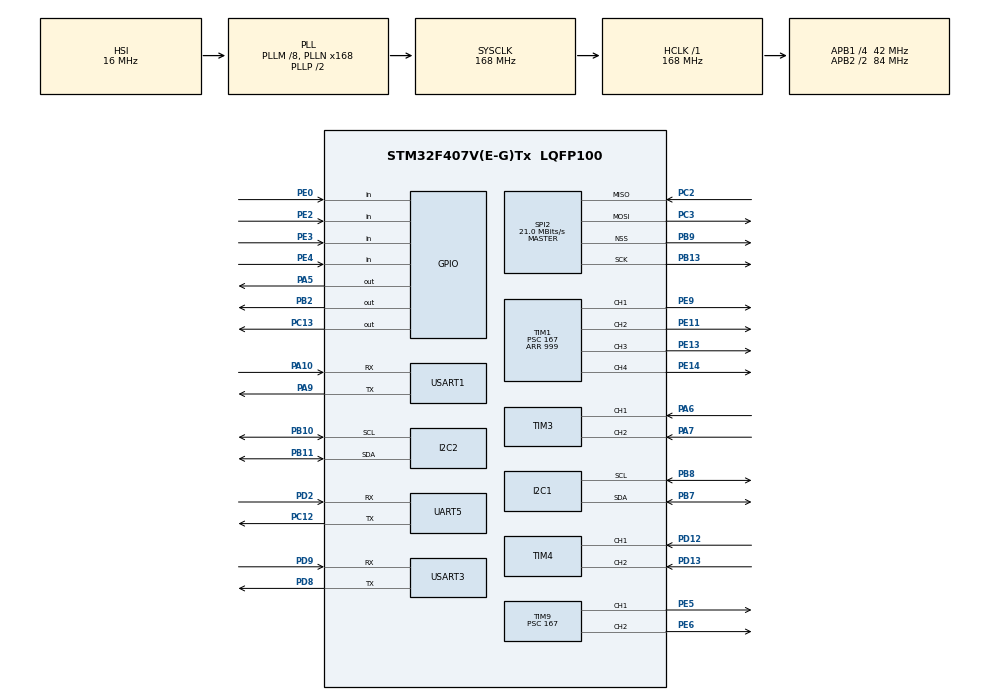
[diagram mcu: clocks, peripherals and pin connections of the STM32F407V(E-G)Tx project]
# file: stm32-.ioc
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Mcu.Family=STM32F4
Mcu.Name=STM32F407V(E-G)Tx
Mcu.Package=LQFP100
NVIC.PriorityGroup=NVIC_PRIORITYGROUP_4
NVIC.TIM8_BRK_TIM12_IRQn=true\:0\:0\:false\:false\:true\:true\:true\:true
NVIC.UART5_IRQn=true\:0\:0\:false\:false\:true\:true\:true\:true
NVIC.USART1_IRQn=true\:0\:0\:false\:false\:true\:true\:true\:true
NVIC.USART3_IRQn=true\:0\:0\:false\:false\:true\:true\:true\:true
PA0-WKUP.Signal=S_TIM2_CH1_ETR
PA1.Signal=S_TIM2_CH2
PA10.Mode=Asynchronous
PA10.Signal=USART1_RX
PA5.Signal=GPIO_Output
PA6.Signal=S_TIM3_CH1
PA7.Signal=S_TIM3_CH2
PA9.Mode=Asynchronous
PA9.Signal=USART1_TX
PB10.Mode=I2C
PB10.Signal=I2C2_SCL
PB11.Mode=I2C
PB11.Signal=I2C2_SDA
PB13.Mode=Full_Duplex_Master
PB13.Signal=SPI2_SCK
PB2.Signal=GPIO_Output
PB7.Mode=I2C
PB7.Signal=I2C1_SDA
PB8.Mode=I2C
PB8.Signal=I2C1_SCL
PB9.Mode=NSS_Signal_Hard_Output
PB9.Signal=SPI2_NSS
PC12.Mode=Asynchronous
PC12.Signal=UART5_TX
PC13-ANTI_TAMP.PinState=GPIO_PIN_RESET
PC13-ANTI_TAMP.Signal=GPIO_Output
PC2.Mode=Full_Duplex_Master
PC2.Signal=SPI2_MISO
PC3.Mode=Full_Duplex_Master
PC3.Signal=SPI2_MOSI
PD12.Signal=S_TIM4_CH1
PD13.Signal=S_TIM4_CH2
PD2.Mode=Asynchronous
PD2.Signal=UART5_RX
PD8.Mode=Asynchronous
PD8.Signal=USART3_TX
PD9.Mode=Asynchronous
PD9.Signal=USART3_RX
PE0.Signal=GPIO_Input
PE11.Signal=S_TIM1_CH2
PE13.Signal=S_TIM1_CH3
PE14.Signal=S_TIM1_CH4
PE2.Signal=GPIO_Input
PE3.Signal=GPIO_Input
PE4.Signal=GPIO_Input
PE5.Signal=S_TIM9_CH1
PE6.Signal=S_TIM9_CH2
PE9.Signal=S_TIM1_CH1
PH0-OSC_IN.Mode=HSE-External-Oscillator
PH0-OSC_IN.Signal=RCC_OSC_IN
PH1-OSC_OUT.Mode=HSE-External-Oscillator
PH1-OSC_OUT.Signal=RCC_OSC_OUT
ProjectManager.HeapSize=0x200
ProjectManager.StackSize=0x400
ProjectManager.TargetToolchain=MDK-ARM V5.32
RCC.48MHZClocksFreq_Value=84000000
RCC.AHBFreq_Value=168000000
RCC.APB1CLKDivider=RCC_HCLK_DIV4
RCC.APB1Freq_Value=42000000
RCC.APB1TimFreq_Value=84000000
RCC.APB2CLKDivider=RCC_HCLK_DIV2
RCC.APB2Freq_Value=84000000
RCC.APB2TimFreq_Value=168000000
RCC.CortexFreq_Value=168000000
RCC.HCLKFreq_Value=168000000
RCC.HSE_VALUE=25000000
RCC.HSI_VALUE=16000000
RCC.LSE_VALUE=32768
RCC.PLLM=8
RCC.PLLN=168
RCC.SYSCLKFreq_VALUE=168000000
RCC.SYSCLKSource=RCC_SYSCLKSOURCE_PLLCLK
RCC.VCOOutputFreq_Value=336000000
SH.S_TIM1_CH1.0=TIM1_CH1,PWM Generation1 CH1
SH.S_TIM1_CH2.0=TIM1_CH2,PWM Generation2 CH2
SH.S_TIM1_CH3.0=TIM1_CH3,PWM Generation3 CH3
SH.S_TIM1_CH4.0=TIM1_CH4,PWM Generation4 CH4
SH.S_TIM2_CH1_ETR.0=TIM2_CH1
SH.S_TIM2_CH2.0=TIM2_CH2
SH.S_TIM3_CH1.0=TIM3_CH1,Encoder_Interface
SH.S_TIM3_CH2.0=TIM3_CH2,Encoder_Interface
SH.S_TIM4_CH1.0=TIM4_CH1,Encoder_Interface
SH.S_TIM4_CH2.0=TIM4_CH2,Encoder_Interface
SH.S_TIM9_CH1.0=TIM9_CH1,PWM Generation1 CH1
SH.S_TIM9_CH2.0=TIM9_CH2,PWM Generation2 CH2
SPI2.CalculateBaudRate=21.0 MBits/s
SPI2.Direction=SPI_DIRECTION_2LINES
SPI2.Mode=SPI_MODE_MASTER
SPI2.VirtualNSS=VM_NSSHARD
SPI2.VirtualType=VM_MASTER
TIM1.AutoReloadPreload=TIM_AUTORELOAD_PRELOAD_ENABLE
TIM1.Channel-PWM\ Generation1\ CH1=TIM_CHANNEL_1
TIM1.Channel-PWM\ Generation2\ CH2=TIM_CHANNEL_2
TIM1.Channel-PWM\ Generation3\ CH3=TIM_CHANNEL_3
TIM1.Channel-PWM\ Generation4\ CH4=TIM_CHANNEL_4
TIM1.Period=999
TIM1.Prescaler=167
TIM12.AutoReloadPreload=TIM_AUTORELOAD_PRELOAD_ENABLE
TIM12.Period=2000-1
TIM12.Prescaler=840-1
TIM3.EncoderMode=TIM_ENCODERMODE_TI12
TIM4.AutoReloadPreload=TIM_AUTORELOAD_PRELOAD_DISABLE
TIM4.EncoderMode=TIM_ENCODERMODE_TI12
TIM9.AutoReloadPreload=TIM_AUTORELOAD_PRELOAD_ENABLE
TIM9.Channel-PWM\ Generation1\ CH1=TIM_CHANNEL_1
TIM9.Channel-PWM\ Generation2\ CH2=TIM_CHANNEL_2
TIM9.Period=2000-1
TIM9.Prescaler=167
TIM9.Pulse-PWM\ Generation1\ CH1=500
TIM9.Pulse-PWM\ Generation2\ CH2=500
UART5.VirtualMode=Asynchronous
USART1.VirtualMode=VM_ASYNC
USART3.VirtualMode=VM_ASYNC
VP_RTC_VS_RTC_Activate.Mode=RTC_Enabled
VP_RTC_VS_RTC_WakeUp_intern.Mode=WakeUp
VP_TIM12_VS_ClockSourceINT.Mode=Internal
VP_TIM1_VS_ClockSourceINT.Mode=Internal
VP_TIM9_VS_ClockSourceINT.Mode=Internal
board=custom

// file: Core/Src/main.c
/* USER CODE BEGIN Header */
/**
  ******************************************************************************
  * @file           : main.c
  * @brief          : Main program body
  ******************************************************************************
  * @attention
  *
  * Copyright (c) 2025 STMicroelectronics.
  * All rights reserved.
  *
  * This software is licensed under terms that can be found in the LICENSE file
  * in the root directory of this software component.
  * If no LICENSE file comes with this software, it is provided AS-IS.
  *
  ******************************************************************************
  */
/* USER CODE END Header */
#include "main.h"
#include "i2c.h"
#include "rtc.h"
#include "spi.h"
#include "tim.h"
#include "usart.h"
#include "gpio.h"

/* USER CODE BEGIN Includes */
#include "main_config.h"

/* USER CODE END Includes */

void SystemClock_Config(void);

int main(void)
{

  /* MCU Configuration--------------------------------------------------------*/

  /* Reset of all peripherals, Initializes the Flash interface and the Systick. */
  HAL_Init();

  /* Configure the system clock */
  SystemClock_Config();

  /* Initialize all configured peripherals */
  MX_GPIO_Init();
  MX_USART1_UART_Init();
  MX_TIM12_Init();
  MX_TIM1_Init();
  MX_I2C2_Init();
  MX_TIM9_Init();
  MX_RTC_Init();
  MX_I2C1_Init();
  MX_TIM4_Init();
  MX_SPI2_Init();
  MX_TIM3_Init();
  MX_UART5_Init();
  MX_USART3_UART_Init();

  /* Infinite loop */

    /* USER CODE BEGIN 3 */

		Loop();

  /* USER CODE END 3 */
}

void SystemClock_Config(void)
{
  RCC_OscInitTypeDef RCC_OscInitStruct = {0};
  RCC_ClkInitTypeDef RCC_ClkInitStruct = {0};

  /** Configure the main internal regulator output voltage
  */
  __HAL_RCC_PWR_CLK_ENABLE();
  __HAL_PWR_VOLTAGESCALING_CONFIG(PWR_REGULATOR_VOLTAGE_SCALE1);

  /** Initializes the RCC Oscillators according to the specified parameters
  * in the RCC_OscInitTypeDef structure.
  */
  RCC_OscInitStruct.OscillatorType = RCC_OSCILLATORTYPE_HSI|RCC_OSCILLATORTYPE_LSI;
  RCC_OscInitStruct.HSIState = RCC_HSI_ON;
  RCC_OscInitStruct.HSICalibrationValue = RCC_HSICALIBRATION_DEFAULT;
  RCC_OscInitStruct.LSIState = RCC_LSI_ON;
  RCC_OscInitStruct.PLL.PLLState = RCC_PLL_ON;
  RCC_OscInitStruct.PLL.PLLSource = RCC_PLLSOURCE_HSI;
  RCC_OscInitStruct.PLL.PLLM = 8;
  RCC_OscInitStruct.PLL.PLLN = 168;
  RCC_OscInitStruct.PLL.PLLP = RCC_PLLP_DIV2;
  RCC_OscInitStruct.PLL.PLLQ = 4;
  if (HAL_RCC_OscConfig(&RCC_OscInitStruct) != HAL_OK)
  {
    Error_Handler();
  }

  /** Initializes the CPU, AHB and APB buses clocks
  */
  RCC_ClkInitStruct.ClockType = RCC_CLOCKTYPE_HCLK|RCC_CLOCKTYPE_SYSCLK
                              |RCC_CLOCKTYPE_PCLK1|RCC_CLOCKTYPE_PCLK2;
  RCC_ClkInitStruct.SYSCLKSource = RCC_SYSCLKSOURCE_PLLCLK;
  RCC_ClkInitStruct.AHBCLKDivider = RCC_SYSCLK_DIV1;
  RCC_ClkInitStruct.APB1CLKDivider = RCC_HCLK_DIV4;
  RCC_ClkInitStruct.APB2CLKDivider = RCC_HCLK_DIV2;

  if (HAL_RCC_ClockConfig(&RCC_ClkInitStruct, FLASH_LATENCY_5) != HAL_OK)
  {
    Error_Handler();
  }
}

void Error_Handler(void)
{
  __disable_irq();
  while (1)
  {
  }
}
